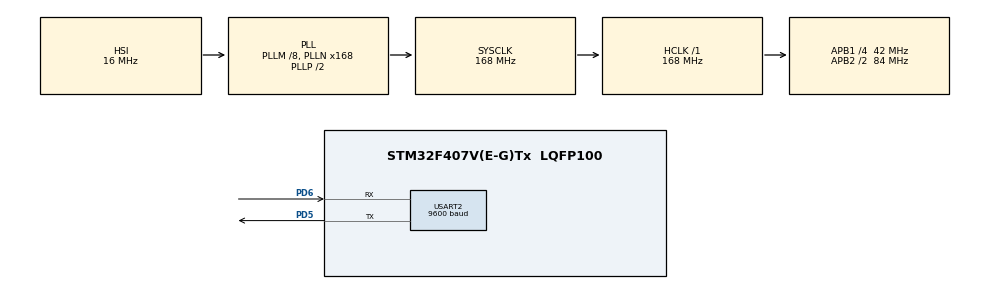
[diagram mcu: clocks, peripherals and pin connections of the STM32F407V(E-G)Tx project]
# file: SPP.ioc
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Mcu.Family=STM32F4
Mcu.Name=STM32F407V(E-G)Tx
Mcu.Package=LQFP100
NVIC.PriorityGroup=NVIC_PRIORITYGROUP_4
NVIC.USART2_IRQn=true\:0\:0\:false\:false\:true\:true\:true
PA13.Mode=Serial_Wire
PA13.Signal=SYS_JTMS-SWDIO
PA14.Mode=Serial_Wire
PA14.Signal=SYS_JTCK-SWCLK
PD5.Mode=Asynchronous
PD5.Signal=USART2_TX
PD6.Mode=Asynchronous
PD6.Signal=USART2_RX
ProjectManager.HeapSize=0x200
ProjectManager.StackSize=0x400
ProjectManager.TargetToolchain=MDK-ARM V5.27
RCC.48MHZClocksFreq_Value=84000000
RCC.AHBFreq_Value=168000000
RCC.APB1CLKDivider=RCC_HCLK_DIV4
RCC.APB1Freq_Value=42000000
RCC.APB1TimFreq_Value=84000000
RCC.APB2CLKDivider=RCC_HCLK_DIV2
RCC.APB2Freq_Value=84000000
RCC.APB2TimFreq_Value=168000000
RCC.CortexFreq_Value=168000000
RCC.HCLKFreq_Value=168000000
RCC.HSE_VALUE=25000000
RCC.HSI_VALUE=16000000
RCC.LSE_VALUE=32768
RCC.PLLM=8
RCC.PLLN=168
RCC.SYSCLKFreq_VALUE=168000000
RCC.SYSCLKSource=RCC_SYSCLKSOURCE_PLLCLK
RCC.VCOOutputFreq_Value=336000000
USART2.BaudRate=9600
USART2.VirtualMode=VM_ASYNC
board=custom

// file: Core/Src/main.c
/* USER CODE BEGIN Header */
/**
  ******************************************************************************
  * @file           : main.c
  * @brief          : Main program body
  ******************************************************************************
  * @attention
  *
  * <h2><center>&copy; Copyright (c) 2021 STMicroelectronics.
  * All rights reserved.</center></h2>
  *
  * This software component is licensed by ST under BSD 3-Clause license,
  * the "License"; You may not use this file except in compliance with the
  * License. You may obtain a copy of the License at:
  *                        opensource.org/licenses/BSD-3-Clause
  *
  ******************************************************************************
  */
/* USER CODE END Header */
#include "main.h"
#include "usart.h"
#include "gpio.h"

/* USER CODE BEGIN Includes */
#include "stdio.h"
#include "string.h"
/* USER CODE END Includes */

/* USER CODE BEGIN PD */
uint8_t rx,rx_buff[500],count = 0;
/* USER CODE END PD */

/* USER CODE BEGIN PM */
void HAL_UART_RxCpltCallback(UART_HandleTypeDef *huart)
{
		if(huart->Instance == USART2)
		{
			HAL_UART_Receive_IT(&huart2,&rx,1);
			rx_buff[count++] = rx;
		}

}
/* USER CODE END PM */

void SystemClock_Config(void);

/* USER CODE BEGIN 0 */
extern UART_HandleTypeDef huart2;

struct __FILE { int handle; /* Add whatever you need here */ };
FILE __stdout;
FILE __stdin;

int fputc(int c, FILE *f) {
  return (HAL_UART_Transmit(&huart2,( uint8_t * )&c,1,1000));
}

int fgetc(FILE *f) {
	uint8_t c;
	HAL_UART_Receive(&huart2,&c,1,0xffff);
	return c;
}

int ferror(FILE *f) {
  /* Your implementation of ferror */
  return EOF;
}

void _ttywrch(int c) {
  HAL_UART_Transmit(&huart2,( uint8_t * )&c,1,1000);
}
/* USER CODE END 0 */

int main(void)
{
  /* USER CODE BEGIN 1 */
  int a,b,result;
	char operation;
  /* USER CODE END 1 */

  /* MCU Configuration--------------------------------------------------------*/

  /* Reset of all peripherals, Initializes the Flash interface and the Systick. */
  HAL_Init();

  /* Configure the system clock */
  SystemClock_Config();

  /* Initialize all configured peripherals */
  MX_GPIO_Init();
  MX_USART2_UART_Init();
  /* USER CODE BEGIN 2 */
  //HAL_UART_Receive_IT(&huart2,&rx,1);
	  printf("calculator example\r");

	printf("please Enter first number = ");
	scanf("%d",&a);
	printf("please Enter operation ");
	scanf("%s",&operation);
	printf("please Enter seconde number = ");
	scanf("%d",&b);
	switch(operation)44411663
	{
		case '+':
			result = a + b;
			break;
		case '-':
			result = a - b;
			break;
		case '*':
			result = a * b;
			break;
		case '/':
			result = a / b;
			break;

	}
	printf("result = %d",result);
  /* USER CODE END 2 */

  /* Infinite loop */
  while (1)
  {

  }
}

void SystemClock_Config(void)
{
  RCC_OscInitTypeDef RCC_OscInitStruct = {0};
  RCC_ClkInitTypeDef RCC_ClkInitStruct = {0};

  /** Configure the main internal regulator output voltage
  */
  __HAL_RCC_PWR_CLK_ENABLE();
  __HAL_PWR_VOLTAGESCALING_CONFIG(PWR_REGULATOR_VOLTAGE_SCALE1);
  /** Initializes the RCC Oscillators according to the specified parameters
  * in the RCC_OscInitTypeDef structure.
  */
  RCC_OscInitStruct.OscillatorType = RCC_OSCILLATORTYPE_HSI;
  RCC_OscInitStruct.HSIState = RCC_HSI_ON;
  RCC_OscInitStruct.HSICalibrationValue = RCC_HSICALIBRATION_DEFAULT;
  RCC_OscInitStruct.PLL.PLLState = RCC_PLL_ON;
  RCC_OscInitStruct.PLL.PLLSource = RCC_PLLSOURCE_HSI;
  RCC_OscInitStruct.PLL.PLLM = 8;
  RCC_OscInitStruct.PLL.PLLN = 168;
  RCC_OscInitStruct.PLL.PLLP = RCC_PLLP_DIV2;
  RCC_OscInitStruct.PLL.PLLQ = 4;
  if (HAL_RCC_OscConfig(&RCC_OscInitStruct) != HAL_OK)
  {
    Error_Handler();
  }
  /** Initializes the CPU, AHB and APB buses clocks
  */
  RCC_ClkInitStruct.ClockType = RCC_CLOCKTYPE_HCLK|RCC_CLOCKTYPE_SYSCLK
                              |RCC_CLOCKTYPE_PCLK1|RCC_CLOCKTYPE_PCLK2;
  RCC_ClkInitStruct.SYSCLKSource = RCC_SYSCLKSOURCE_PLLCLK;
  RCC_ClkInitStruct.AHBCLKDivider = RCC_SYSCLK_DIV1;
  RCC_ClkInitStruct.APB1CLKDivider = RCC_HCLK_DIV4;
  RCC_ClkInitStruct.APB2CLKDivider = RCC_HCLK_DIV2;

  if (HAL_RCC_ClockConfig(&RCC_ClkInitStruct, FLASH_LATENCY_5) != HAL_OK)
  {
    Error_Handler();
  }
}

void Error_Handler(void)
{
  __disable_irq();
  while (1)
  {
  }
}

/************************ (C) COPYRIGHT STMicroelectronics *****END OF FILE****/
